VERSION ""

NS_ :

BS_:

BU_: ROS RAPTOR

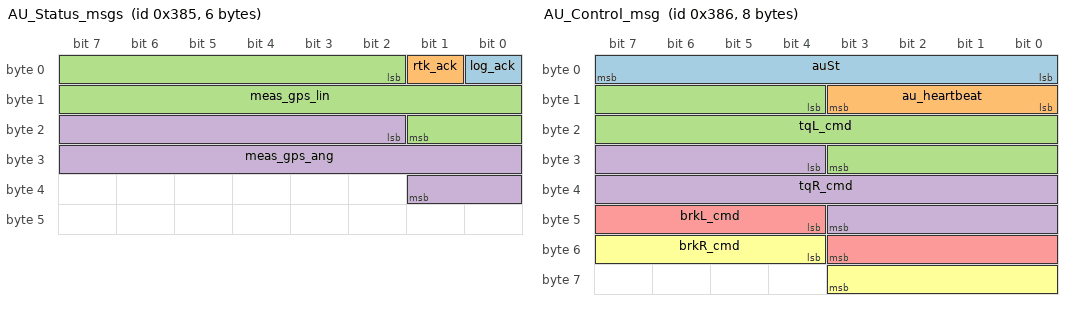
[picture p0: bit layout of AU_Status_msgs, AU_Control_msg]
BO_ 901 AU_Status_msgs: 6 ROS
 SG_ log_ack : 0|1@1+ (1,0) [0|1] "-" RAPTOR
 SG_ rtk_ack : 1|1@1+ (1,0) [0|1] "-" RAPTOR
 SG_ meas_gps_lin : 2|16@1- (0.001,0) [-32.768|+32.767] "m/s" RAPTOR
 SG_ meas_gps_ang : 18|16@1- (0.0001,0) [-3.2768|+3.2767] "rad/s" RAPTOR

BO_ 902 AU_Control_msg: 8 ROS
 SG_ auSt : 0|8@1+ (1,0) [0|255] "-" RAPTOR
 SG_ au_heartbeat : 8|4@1+ (1,0) [0|15] "-" RAPTOR
 SG_ tqL_cmd : 12|16@1- (0.01526,0) [-500|500] "N-m" RAPTOR
 SG_ tqR_cmd : 28|16@1- (0.01526,0) [-500|500] "N-m" RAPTOR
 SG_ brkL_cmd: 44|8@1+ (0.0039,0) [0|1] "bar" RAPTOR
 SG_ brkR_cmd : 52|8@1+ (0.0039,0) [0|1] "bar" RAPTOR

CM_ BO_ 901 "Measured velocities, Logging and RTK status";
CM_ BO_ 902 "Mobility commands form ROS (Torque and Brakes)";
